AUTOSAR XML (schema 4-0-3)
package /ComponentTypes
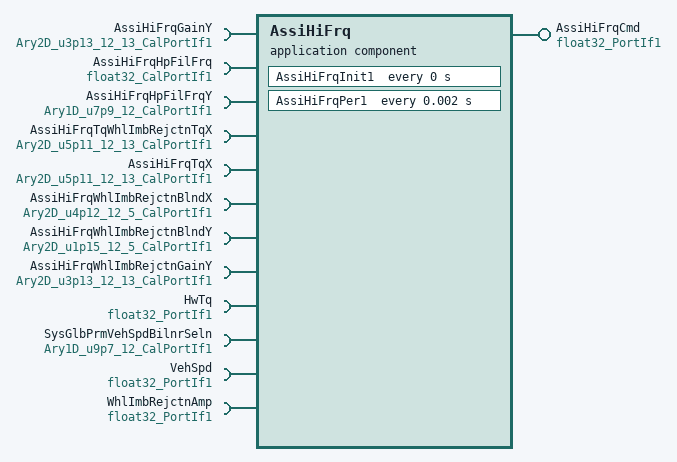
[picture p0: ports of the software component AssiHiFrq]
  application sw component type AssiHiFrq
    provide port AssiHiFrqCmd: nonqueued-sender-com-spec{data-element=Val, init-value=0}, provided-interface=float32_PortIf1
    12 x require port:
      AssiHiFrqGainY: parameter-require-com-spec{init-value=12 x [2048, 1638, 1065, 655, 328, 82, 0, 0, 0, 0, 0, 0, 0], parameter=Ary2D}, required-interface=Ary2D_u3p13_12_13_CalPortIf1
      AssiHiFrqHpFilFrq: parameter-require-com-spec{init-value=15, parameter=Val}, required-interface=float32_CalPortIf1
      AssiHiFrqHpFilFrqY: parameter-require-com-spec{init-value=12 x 4096, parameter=Ary1D}, required-interface=Ary1D_u7p9_12_CalPortIf1
      AssiHiFrqTqWhlImbRejctnTqX: parameter-require-com-spec{init-value=12 x [0, 512, 1024, 1536, 2048, 2560, 3072, 4096, 8192, 12288, 15360, 15872, 16384], parameter=Ary2D}, required-interface=Ary2D_u5p11_12_13_CalPortIf1
      AssiHiFrqTqX: parameter-require-com-spec{init-value=12 x [0, 512, 1024, 1536, 2048, 2560, 3072, 4096, 8192, 12288, 15360, 15872, 16384], parameter=Ary2D}, required-interface=Ary2D_u5p11_12_13_CalPortIf1
      AssiHiFrqWhlImbRejctnBlndX: parameter-require-com-spec{init-value=12 x [0, 1024, 2048, 3072, 4506], parameter=Ary2D}, required-interface=Ary2D_u4p12_12_5_CalPortIf1
      AssiHiFrqWhlImbRejctnBlndY: parameter-require-com-spec{init-value=12 x 5 x 0, parameter=Ary2D}, required-interface=Ary2D_u1p15_12_5_CalPortIf1
      AssiHiFrqWhlImbRejctnGainY: parameter-require-com-spec{init-value=12 x [2048, 1638, 1065, 655, 328, 82, 0, 0, 0, 0, 0, 0, 0], parameter=Ary2D}, required-interface=Ary2D_u3p13_12_13_CalPortIf1
      HwTq: nonqueued-receiver-com-spec{data-element=Val, filter=data-filter-type=ALWAYS, init-value=0}, required-interface=float32_PortIf1
      SysGlbPrmVehSpdBilnrSeln: parameter-require-com-spec{init-value=[0, 640, 1920, 3840, 7680, 10240, 12800, 15360, 19200, 23040, 25600, 28160], parameter=Ary1D}, required-interface=Ary1D_u9p7_12_CalPortIf1
      VehSpd: nonqueued-receiver-com-spec{data-element=Val, filter=data-filter-type=ALWAYS, init-value=0}, required-interface=float32_PortIf1
      WhlImbRejctnAmp: nonqueued-receiver-com-spec{data-element=Val, filter=data-filter-type=ALWAYS, init-value=0}, required-interface=float32_PortIf1
    behavior AssiHiFrq_InternalBehavior
      ar-typed-per-instance-memorys:
        4 x data, all with sw-calibration-access=READ-ONLY:
          dAssiHiFrqGain: type=float32
          dAssiHiFrqGainBlnd: type=float32
          dAssiHiFrqGainWhlImbRejtcnZero: type=float32
          HwTqHpFil: type=FilHpRec1
      timing event AssiHiFrq_InitEvent: start-on-event=AssiHiFrqInit1, period=0
      timing event TMT_AssiHiFrqPer1: start-on-event=AssiHiFrqPer1, period=0.002
      runnable AssiHiFrqInit1
      runnable AssiHiFrqPer1
        data-receive-point-by-arguments:
          access REC_HwTq_Val: accessed-variable=HwTq.Val
          access REC_VehSpd_Val: accessed-variable=VehSpd.Val
          access REC_WhlImbRejctnAmp_Val: accessed-variable=WhlImbRejctnAmp.Val
        data-send-points:
          access SEND_AssiHiFrqCmd_Val: accessed-variable=AssiHiFrqCmd.Val
  swc implementation AssiHiFrq_Implementation: behavior=AssiHiFrq_InternalBehavior
    code-descriptors:
      code Default: artifact-descriptors=autosar-engineering-object={short-label=Default, category=SWSRC}
